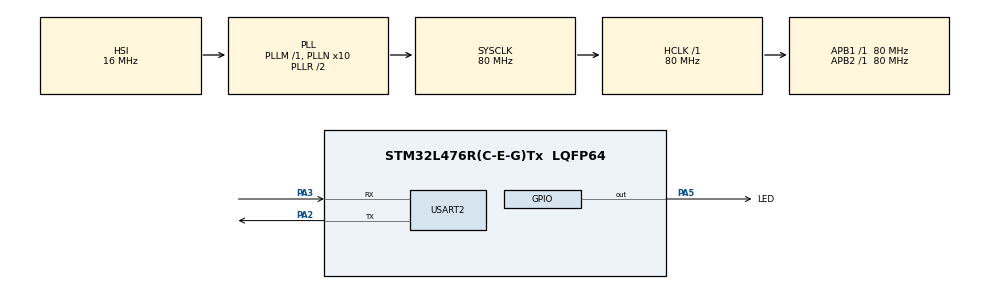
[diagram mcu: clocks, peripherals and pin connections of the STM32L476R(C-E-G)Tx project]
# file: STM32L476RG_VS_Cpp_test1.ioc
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Dma.Request0=USART2_TX
Dma.USART2_TX.0.Direction=DMA_MEMORY_TO_PERIPH
Dma.USART2_TX.0.Instance=DMA1_Channel7
Dma.USART2_TX.0.MemDataAlignment=DMA_MDATAALIGN_BYTE
Dma.USART2_TX.0.MemInc=DMA_MINC_ENABLE
Dma.USART2_TX.0.Mode=DMA_NORMAL
Dma.USART2_TX.0.PeriphDataAlignment=DMA_PDATAALIGN_BYTE
Dma.USART2_TX.0.PeriphInc=DMA_PINC_DISABLE
Dma.USART2_TX.0.Priority=DMA_PRIORITY_LOW
Mcu.Family=STM32L4
Mcu.Name=STM32L476R(C-E-G)Tx
Mcu.Package=LQFP64
NVIC.DMA1_Channel7_IRQn=true\:0\:0\:false\:false\:true\:false\:true\:true
NVIC.PriorityGroup=NVIC_PRIORITYGROUP_4
NVIC.USART2_IRQn=true\:0\:0\:false\:false\:true\:false\:true\:true
PA2.Mode=Asynchronous
PA2.Signal=USART2_TX
PA3.Mode=Asynchronous
PA3.Signal=USART2_RX
PA5.GPIO_Label=LED
PA5.Signal=GPIO_Output
ProjectManager.HeapSize=0x200
ProjectManager.StackSize=0x400
ProjectManager.TargetToolchain=CMake
RCC.ADCFreq_Value=64000000
RCC.AHBFreq_Value=80000000
RCC.APB1Freq_Value=80000000
RCC.APB1TimFreq_Value=80000000
RCC.APB2Freq_Value=80000000
RCC.APB2TimFreq_Value=80000000
RCC.CortexFreq_Value=80000000
RCC.HCLKFreq_Value=80000000
RCC.HSE_VALUE=8000000
RCC.HSI_VALUE=16000000
RCC.LSE_VALUE=32768
RCC.MSI_VALUE=4000000
RCC.PLLN=10
RCC.PLLSourceVirtual=RCC_PLLSOURCE_HSI
RCC.SYSCLKFreq_VALUE=80000000
RCC.SYSCLKSource=RCC_SYSCLKSOURCE_PLLCLK
RCC.USBFreq_Value=64000000
RCC.VCOOutputFreq_Value=160000000
USART2.VirtualMode-Asynchronous=VM_ASYNC
board=custom

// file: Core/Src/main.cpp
/* USER CODE BEGIN Header */
/**
  ******************************************************************************
  * @file           : main.c
  * @brief          : Main program body
  ******************************************************************************
  * @attention
  *
  * Copyright (c) 2025 STMicroelectronics.
  * All rights reserved.
  *
  * This software is licensed under terms that can be found in the LICENSE file
  * in the root directory of this software component.
  * If no LICENSE file comes with this software, it is provided AS-IS.
  *
  ******************************************************************************
  */
/* USER CODE END Header */
#include "main.h"
#include "stm32l4xx_hal_gpio.h"
#include "stm32l4xx_hal_uart.h"
#include <string.h>
#include "Logger.hpp"
#include "Logger_UART_Interface.hpp"

UART_HandleTypeDef huart2;
DMA_HandleTypeDef hdma_usart2_tx;

void SystemClock_Config(void);
static void MX_GPIO_Init(void);
static void MX_DMA_Init(void);
static void MX_USART2_UART_Init(void);

int main(void)
{

  /* MCU Configuration--------------------------------------------------------*/

  /* Reset of all peripherals, Initializes the Flash interface and the Systick. */
  HAL_Init();

  /* Configure the system clock */
  SystemClock_Config();

  /* Initialize all configured peripherals */
  MX_GPIO_Init();
  MX_DMA_Init();
  MX_USART2_UART_Init();

  /* USER CODE BEGIN 2 */
  // Create logger UART interface
  Logger_UART_Interface uart_logger(&huart2);

  // Initialize the logger with UART output
  LOG_INIT(&uart_logger);

  // Simple test logs
  LOG_INFO("Logger initialized successfully");
  HAL_Delay(50); // Toggle LED every 50 ms

  int battery_percent = 75;
  int error_code = 100;

  LOG_DEBUG("Loop tick: %lu", HAL_GetTick());
  LOG_WARN("Battery low: %d%%", battery_percent);
  LOG_ERROR("Sensor error: code=%d", error_code);

  /* USER CODE END 2 */

  /* Infinite loop */
  while (1)
  {

    /* USER CODE BEGIN 3 */

    // Process the logs to send them via UART
    LOG_PROCESS();

    HAL_GPIO_TogglePin(LED_GPIO_Port, LED_Pin);
    HAL_Delay(500); // Toggle LED every 500 ms
  }
  /* USER CODE END 3 */
}

void SystemClock_Config(void)
{
  RCC_OscInitTypeDef RCC_OscInitStruct = {0};
  RCC_ClkInitTypeDef RCC_ClkInitStruct = {0};

  /** Configure the main internal regulator output voltage
  */
  if (HAL_PWREx_ControlVoltageScaling(PWR_REGULATOR_VOLTAGE_SCALE1) != HAL_OK)
  {
    Error_Handler();
  }

  /** Initializes the RCC Oscillators according to the specified parameters
  * in the RCC_OscInitTypeDef structure.
  */
  RCC_OscInitStruct.OscillatorType = RCC_OSCILLATORTYPE_HSI;
  RCC_OscInitStruct.HSIState = RCC_HSI_ON;
  RCC_OscInitStruct.HSICalibrationValue = RCC_HSICALIBRATION_DEFAULT;
  RCC_OscInitStruct.PLL.PLLState = RCC_PLL_ON;
  RCC_OscInitStruct.PLL.PLLSource = RCC_PLLSOURCE_HSI;
  RCC_OscInitStruct.PLL.PLLM = 1;
  RCC_OscInitStruct.PLL.PLLN = 10;
  RCC_OscInitStruct.PLL.PLLP = RCC_PLLP_DIV7;
  RCC_OscInitStruct.PLL.PLLQ = RCC_PLLQ_DIV2;
  RCC_OscInitStruct.PLL.PLLR = RCC_PLLR_DIV2;
  if (HAL_RCC_OscConfig(&RCC_OscInitStruct) != HAL_OK)
  {
    Error_Handler();
  }

  /** Initializes the CPU, AHB and APB buses clocks
  */
  RCC_ClkInitStruct.ClockType = RCC_CLOCKTYPE_HCLK|RCC_CLOCKTYPE_SYSCLK
                              |RCC_CLOCKTYPE_PCLK1|RCC_CLOCKTYPE_PCLK2;
  RCC_ClkInitStruct.SYSCLKSource = RCC_SYSCLKSOURCE_PLLCLK;
  RCC_ClkInitStruct.AHBCLKDivider = RCC_SYSCLK_DIV1;
  RCC_ClkInitStruct.APB1CLKDivider = RCC_HCLK_DIV1;
  RCC_ClkInitStruct.APB2CLKDivider = RCC_HCLK_DIV1;

  if (HAL_RCC_ClockConfig(&RCC_ClkInitStruct, FLASH_LATENCY_4) != HAL_OK)
  {
    Error_Handler();
  }
}

static void MX_USART2_UART_Init(void)
{

  huart2.Instance = USART2;
  huart2.Init.BaudRate = 115200;
  huart2.Init.WordLength = UART_WORDLENGTH_8B;
  huart2.Init.StopBits = UART_STOPBITS_1;
  huart2.Init.Parity = UART_PARITY_NONE;
  huart2.Init.Mode = UART_MODE_TX_RX;
  huart2.Init.HwFlowCtl = UART_HWCONTROL_NONE;
  huart2.Init.OverSampling = UART_OVERSAMPLING_16;
  huart2.Init.OneBitSampling = UART_ONE_BIT_SAMPLE_DISABLE;
  huart2.AdvancedInit.AdvFeatureInit = UART_ADVFEATURE_NO_INIT;
  if (HAL_UART_Init(&huart2) != HAL_OK)
  {
    Error_Handler();
  }

}

static void MX_DMA_Init(void)
{

  /* DMA controller clock enable */
  __HAL_RCC_DMA1_CLK_ENABLE();

  // Configure DMA request hdma_usart2_tx on DMA1_Channel7
  hdma_usart2_tx.Instance = DMA1_Channel7;
  hdma_usart2_tx.Init.Request = DMA_REQUEST_2;
  hdma_usart2_tx.Init.Direction = DMA_MEMORY_TO_PERIPH;
  hdma_usart2_tx.Init.PeriphInc = DMA_PINC_DISABLE;
  hdma_usart2_tx.Init.MemInc = DMA_MINC_ENABLE;
  hdma_usart2_tx.Init.PeriphDataAlignment = DMA_PDATAALIGN_BYTE;
  hdma_usart2_tx.Init.MemDataAlignment = DMA_MDATAALIGN_BYTE;
  hdma_usart2_tx.Init.Mode = DMA_NORMAL;
  hdma_usart2_tx.Init.Priority = DMA_PRIORITY_LOW;
  if (HAL_DMA_Init(&hdma_usart2_tx) != HAL_OK)
  {
  Error_Handler();
  }

  // Link DMA handle to UART handle
  __HAL_LINKDMA(&huart2, hdmatx, hdma_usart2_tx);

  /* DMA interrupt init */
  /* DMA1_Channel7_IRQn interrupt configuration */
  HAL_NVIC_SetPriority(DMA1_Channel7_IRQn, 0, 0);
  HAL_NVIC_EnableIRQ(DMA1_Channel7_IRQn);

  /* USER CODE BEGIN DMA_Init 1 */

}

static void MX_GPIO_Init(void)
{
  GPIO_InitTypeDef GPIO_InitStruct = {0};

  /* GPIO Ports Clock Enable */
  __HAL_RCC_GPIOA_CLK_ENABLE();

  /*Configure GPIO pin Output Level */
  HAL_GPIO_WritePin(LED_GPIO_Port, LED_Pin, GPIO_PIN_RESET);

  /*Configure GPIO pin : LED_Pin */
  GPIO_InitStruct.Pin = LED_Pin;
  GPIO_InitStruct.Mode = GPIO_MODE_OUTPUT_PP;
  GPIO_InitStruct.Pull = GPIO_NOPULL;
  GPIO_InitStruct.Speed = GPIO_SPEED_FREQ_LOW;
  HAL_GPIO_Init(LED_GPIO_Port, &GPIO_InitStruct);

}

void Error_Handler(void)
{
  __disable_irq();
  while (1)
  {
  }
}
